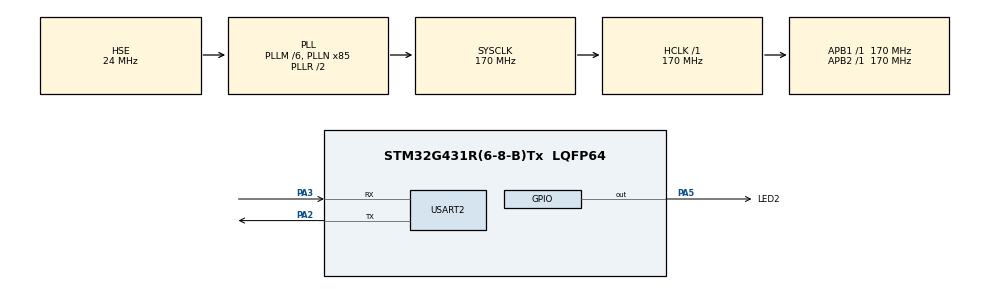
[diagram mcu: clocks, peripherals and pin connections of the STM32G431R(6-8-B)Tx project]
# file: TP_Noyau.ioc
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FREERTOS.Tasks01=defaultTask,24,128,StartDefaultTask,Default,NULL,Dynamic,NULL,NULL
Mcu.Family=STM32G4
Mcu.Name=STM32G431R(6-8-B)Tx
Mcu.Package=LQFP64
NVIC.PriorityGroup=NVIC_PRIORITYGROUP_4
NVIC.TIM2_IRQn=true\:5\:0\:false\:false\:true\:true\:true\:true\:true
NVIC.TIM6_DAC_IRQn=true\:15\:0\:false\:false\:true\:false\:true\:true\:true
NVIC.TimeBase=TIM6_DAC_IRQn
NVIC.TimeBaseIP=TIM6
PA13.Mode=Serial_Wire
PA13.Signal=SYS_JTMS-SWDIO
PA14.Mode=Serial_Wire
PA14.Signal=SYS_JTCK-SWCLK
PA2.Mode=Asynchronous
PA2.Signal=USART2_TX
PA3.Mode=Asynchronous
PA3.Signal=USART2_RX
PA5.GPIO_Label=LED2
PA5.Signal=GPIO_Output
PF0-OSC_IN.Mode=HSE-External-Oscillator
PF0-OSC_IN.Signal=RCC_OSC_IN
PF1-OSC_OUT.Mode=HSE-External-Oscillator
PF1-OSC_OUT.Signal=RCC_OSC_OUT
ProjectManager.HeapSize=0x200
ProjectManager.StackSize=0x400
ProjectManager.TargetToolchain=STM32CubeIDE
RCC.ADC12Freq_Value=170000000
RCC.AHBFreq_Value=170000000
RCC.APB1Freq_Value=170000000
RCC.APB1TimFreq_Value=170000000
RCC.APB2Freq_Value=170000000
RCC.APB2TimFreq_Value=170000000
RCC.CortexFreq_Value=170000000
RCC.EXTERNAL_CLOCK_VALUE=12288000
RCC.HCLKFreq_Value=170000000
RCC.HSE_VALUE=24000000
RCC.HSI48_VALUE=48000000
RCC.HSI_VALUE=16000000
RCC.LSE_VALUE=32768
RCC.PLLM=RCC_PLLM_DIV6
RCC.PLLN=85
RCC.PLLSourceVirtual=RCC_PLLSOURCE_HSE
RCC.RTCClockSelection=RCC_RTCCLKSOURCE_LSE
RCC.SYSCLKFreq_VALUE=170000000
RCC.SYSCLKSource=RCC_SYSCLKSOURCE_PLLCLK
RCC.USBFreq_Value=170000000
RCC.VCOOutputFreq_Value=340000000
USART2.VirtualMode-Asynchronous=VM_ASYNC
VP_FREERTOS_VS_CMSIS_V2.Mode=CMSIS_V2
VP_SYS_VS_DBSignals.Mode=DisableDeadBatterySignals
VP_SYS_VS_tim6.Mode=TIM6
VP_TIM2_VS_ClockSourceINT.Mode=Internal
board=NUCLEO-G431RB

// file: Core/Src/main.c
/* USER CODE BEGIN Header */
/**
 ******************************************************************************
 * @file           : main.c
 * @brief          : Main program body
 ******************************************************************************
 * @attention
 *
 * Copyright (c) 2024 STMicroelectronics.
 * All rights reserved.
 *
 * This software is licensed under terms that can be found in the LICENSE file
 * in the root directory of this software component.
 * If no LICENSE file comes with this software, it is provided AS-IS.
 *
 ******************************************************************************
 */
/* USER CODE END Header */
#include "main.h"
#include "cmsis_os.h"

/* USER CODE BEGIN Includes */

#include <stdio.h>
#include <string.h>
#include <FreeRTOS.h>
#include "task.h"
#include "semphr.h"

/* USER CODE END Includes */

TIM_HandleTypeDef htim2;

UART_HandleTypeDef huart2;

/* Definitions for defaultTask */
osThreadId_t defaultTaskHandle;
const osThreadAttr_t defaultTask_attributes = {
  .name = "defaultTask",
  .priority = (osPriority_t) osPriorityNormal,
  .stack_size = 128 * 4
};
/* USER CODE BEGIN PV */

TaskHandle_t LED_TaskHandle;
TaskHandle_t Give_TaskHandle;
TaskHandle_t Take_TaskHandle;

QueueHandle_t timer_queue;
uint32_t timerValue;
uint32_t receivedValue;

SemaphoreHandle_t sem;

/* USER CODE END PV */

void SystemClock_Config(void);
static void MX_GPIO_Init(void);
static void MX_USART2_UART_Init(void);
static void MX_TIM2_Init(void);
void StartDefaultTask(void *argument);

/* USER CODE BEGIN 0 */

int __io_putchar(int ch) {
	HAL_UART_Transmit(&huart2, (uint8_t *)&ch, 1, HAL_MAX_DELAY);
	return ch;
}

void LED_Task()
{
	while(1)
	{
		HAL_GPIO_TogglePin(GPIOA, GPIO_PIN_5);
		if(HAL_GPIO_ReadPin(GPIOA, GPIO_PIN_5) == GPIO_PIN_SET)
		{
			//printf("LED ON\r\n");
		}
		else
		{
			//printf("LED OFF\r\n");
		}
		vTaskDelay(100/portTICK_PERIOD_MS); // portTICK_PERIOD_MS pour convertir les ticks en ms
	}
}

void give_Task()
{
	while(1)
	{
		timerValue = __HAL_TIM_GET_COUNTER(&htim2);
		printf("TimeValue from Give Task:  %lu \r\n", timerValue);
		if(xQueueSend(timer_queue, &timerValue, 0) == pdTRUE)
		{
			printf("TimeValue donnée \r\n");
		}
		//xSemaphoreGive(sem);
		xTaskNotifyGive(Take_TaskHandle);
		vTaskDelay(1000/portTICK_PERIOD_MS);
	}

}

void take_Task()
{
	while(1)
	{
		if(ulTaskNotifyTake(pdTRUE, 10000/portTICK_PERIOD_MS ))
		{
			if(xQueueSend(timer_queue, &receivedValue, portMAX_DELAY) == pdTRUE)
					{
						printf("TimeValue:  %lu \r\n", receivedValue);
					}
			vTaskDelay(1000/portTICK_PERIOD_MS);
		}
		else
		{
			printf("Task_take n'a pas pris le sem \r\n");
			break;
		}
		/*
		if (xSemaphoreTake(sem, 1000/portTICK_PERIOD_MS) == pdTRUE)
		{
			printf("Task_take a pris le sem\r\n");
			vTaskDelay(100/portTICK_PERIOD_MS);
		}
		else
		{
			printf("Task_take n'a pas pris le sem \r\n");
			break;
		}
		*/

	}

}

/* USER CODE END 0 */

int main(void)
{

  /* MCU Configuration--------------------------------------------------------*/

  /* Reset of all peripherals, Initializes the Flash interface and the Systick. */
  HAL_Init();

  /* Configure the system clock */
  SystemClock_Config();

  /* Initialize all configured peripherals */
  MX_GPIO_Init();
  MX_USART2_UART_Init();
  MX_TIM2_Init();
  /* USER CODE BEGIN 2 */

	printf("==== TD Noyau ==== \r\n");

	sem = xSemaphoreCreateBinary();

	timer_queue = xQueueCreate(100, sizeof(uint32_t));

	xTaskCreate(give_Task, "GiveTask", 128, NULL, 2, &Give_TaskHandle);
	xTaskCreate(take_Task, "TakeTask", 128, NULL, 1, &Take_TaskHandle);
	xTaskCreate(LED_Task, "LED_Task", 128, NULL, 3, &LED_TaskHandle);

	HAL_TIM_Base_Start_IT(&htim2);
  /* USER CODE END 2 */

  /* Init scheduler */
  osKernelInitialize();

  /* Create the thread(s) */
  /* creation of defaultTask */
  defaultTaskHandle = osThreadNew(StartDefaultTask, NULL, &defaultTask_attributes);

  /* Start scheduler */
  osKernelStart();

  /* We should never get here as control is now taken by the scheduler */

  /* Infinite loop */
	while (1)
	{

	}
}

void SystemClock_Config(void)
{
  RCC_OscInitTypeDef RCC_OscInitStruct = {0};
  RCC_ClkInitTypeDef RCC_ClkInitStruct = {0};

  /** Configure the main internal regulator output voltage
  */
  HAL_PWREx_ControlVoltageScaling(PWR_REGULATOR_VOLTAGE_SCALE1_BOOST);

  /** Initializes the RCC Oscillators according to the specified parameters
  * in the RCC_OscInitTypeDef structure.
  */
  RCC_OscInitStruct.OscillatorType = RCC_OSCILLATORTYPE_HSE;
  RCC_OscInitStruct.HSEState = RCC_HSE_ON;
  RCC_OscInitStruct.PLL.PLLState = RCC_PLL_ON;
  RCC_OscInitStruct.PLL.PLLSource = RCC_PLLSOURCE_HSE;
  RCC_OscInitStruct.PLL.PLLM = RCC_PLLM_DIV6;
  RCC_OscInitStruct.PLL.PLLN = 85;
  RCC_OscInitStruct.PLL.PLLP = RCC_PLLP_DIV2;
  RCC_OscInitStruct.PLL.PLLQ = RCC_PLLQ_DIV2;
  RCC_OscInitStruct.PLL.PLLR = RCC_PLLR_DIV2;
  if (HAL_RCC_OscConfig(&RCC_OscInitStruct) != HAL_OK)
  {
    Error_Handler();
  }

  /** Initializes the CPU, AHB and APB buses clocks
  */
  RCC_ClkInitStruct.ClockType = RCC_CLOCKTYPE_HCLK|RCC_CLOCKTYPE_SYSCLK
                              |RCC_CLOCKTYPE_PCLK1|RCC_CLOCKTYPE_PCLK2;
  RCC_ClkInitStruct.SYSCLKSource = RCC_SYSCLKSOURCE_PLLCLK;
  RCC_ClkInitStruct.AHBCLKDivider = RCC_SYSCLK_DIV1;
  RCC_ClkInitStruct.APB1CLKDivider = RCC_HCLK_DIV1;
  RCC_ClkInitStruct.APB2CLKDivider = RCC_HCLK_DIV1;

  if (HAL_RCC_ClockConfig(&RCC_ClkInitStruct, FLASH_LATENCY_4) != HAL_OK)
  {
    Error_Handler();
  }
}

static void MX_TIM2_Init(void)
{

  TIM_ClockConfigTypeDef sClockSourceConfig = {0};
  TIM_MasterConfigTypeDef sMasterConfig = {0};

  htim2.Instance = TIM2;
  htim2.Init.Prescaler = 0;
  htim2.Init.CounterMode = TIM_COUNTERMODE_UP;
  htim2.Init.Period = 4294967295;
  htim2.Init.ClockDivision = TIM_CLOCKDIVISION_DIV1;
  htim2.Init.AutoReloadPreload = TIM_AUTORELOAD_PRELOAD_DISABLE;
  if (HAL_TIM_Base_Init(&htim2) != HAL_OK)
  {
    Error_Handler();
  }
  sClockSourceConfig.ClockSource = TIM_CLOCKSOURCE_INTERNAL;
  if (HAL_TIM_ConfigClockSource(&htim2, &sClockSourceConfig) != HAL_OK)
  {
    Error_Handler();
  }
  sMasterConfig.MasterOutputTrigger = TIM_TRGO_RESET;
  sMasterConfig.MasterSlaveMode = TIM_MASTERSLAVEMODE_DISABLE;
  if (HAL_TIMEx_MasterConfigSynchronization(&htim2, &sMasterConfig) != HAL_OK)
  {
    Error_Handler();
  }

}

static void MX_USART2_UART_Init(void)
{

  huart2.Instance = USART2;
  huart2.Init.BaudRate = 115200;
  huart2.Init.WordLength = UART_WORDLENGTH_8B;
  huart2.Init.StopBits = UART_STOPBITS_1;
  huart2.Init.Parity = UART_PARITY_NONE;
  huart2.Init.Mode = UART_MODE_TX_RX;
  huart2.Init.HwFlowCtl = UART_HWCONTROL_NONE;
  huart2.Init.OverSampling = UART_OVERSAMPLING_16;
  huart2.Init.OneBitSampling = UART_ONE_BIT_SAMPLE_DISABLE;
  huart2.Init.ClockPrescaler = UART_PRESCALER_DIV1;
  huart2.AdvancedInit.AdvFeatureInit = UART_ADVFEATURE_NO_INIT;
  if (HAL_UART_Init(&huart2) != HAL_OK)
  {
    Error_Handler();
  }
  if (HAL_UARTEx_SetTxFifoThreshold(&huart2, UART_TXFIFO_THRESHOLD_1_8) != HAL_OK)
  {
    Error_Handler();
  }
  if (HAL_UARTEx_SetRxFifoThreshold(&huart2, UART_RXFIFO_THRESHOLD_1_8) != HAL_OK)
  {
    Error_Handler();
  }
  if (HAL_UARTEx_DisableFifoMode(&huart2) != HAL_OK)
  {
    Error_Handler();
  }

}

static void MX_GPIO_Init(void)
{
  GPIO_InitTypeDef GPIO_InitStruct = {0};

  /* GPIO Ports Clock Enable */
  __HAL_RCC_GPIOF_CLK_ENABLE();
  __HAL_RCC_GPIOA_CLK_ENABLE();

  /*Configure GPIO pin Output Level */
  HAL_GPIO_WritePin(LED2_GPIO_Port, LED2_Pin, GPIO_PIN_RESET);

  /*Configure GPIO pin : LED2_Pin */
  GPIO_InitStruct.Pin = LED2_Pin;
  GPIO_InitStruct.Mode = GPIO_MODE_OUTPUT_PP;
  GPIO_InitStruct.Pull = GPIO_NOPULL;
  GPIO_InitStruct.Speed = GPIO_SPEED_FREQ_LOW;
  HAL_GPIO_Init(LED2_GPIO_Port, &GPIO_InitStruct);

}

void StartDefaultTask(void *argument)
{
  for(;;)
  {
    osDelay(1);
  }
}

void HAL_TIM_PeriodElapsedCallback(TIM_HandleTypeDef *htim)
{
  if (htim->Instance == TIM6) {
    HAL_IncTick();
  }
}

void Error_Handler(void)
{
	__disable_irq();
	while (1)
	{
	}
}
